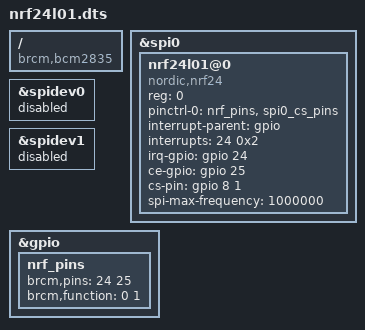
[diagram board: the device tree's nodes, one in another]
/dts-v1/;
/plugin/;

/ {
        compatible = "brcm,bcm2835", "brcm,bcm2708", "brcm,bcm2709";

        fragment@0 {
                target = <&spi0>;
                __overlay__ {
                        status = "okay";
                };
        };

        fragment@1 {
                target = <&spidev0>;
                __overlay__ {
                        status = "disabled";                   
                };
        };

        fragment@2 {
                target = <&spidev1>;
                __overlay__ {
                        status = "disabled";                   
                };
        };

        fragment@3 {
                target = <&gpio>;
                __overlay__ {
                        nrf_pins: nrf_pins {
                                brcm,pins = <24 25>;
                                brcm,function = <0 1>; /* in out */
                        };                  
                };
        };

        fragment@4 {
                target = <&spi0>;
                __overlay__ {
                        #address-cells = <1>;
                        #size-cells = <0>;

                        nrf24l01@0 {
                                compatible = "nordic,nrf24";
                                reg = <0>; /* CS0 */
                                pinctrl-names = "default";
                                pinctrl-0 = <&nrf_pins &spi0_cs_pins>;
                                interrupt-parent = <&gpio>;
                                interrupts = <24 0x2>; /* falling edge */
                                irq-gpio = <&gpio 24 0>;
                                ce-gpio = <&gpio 25 0>;
                                cs-pin = <&gpio 8 1>;
                                spi-max-frequency = <1000000>;
                                status = "okay";   
                        };

                };
        };
};
